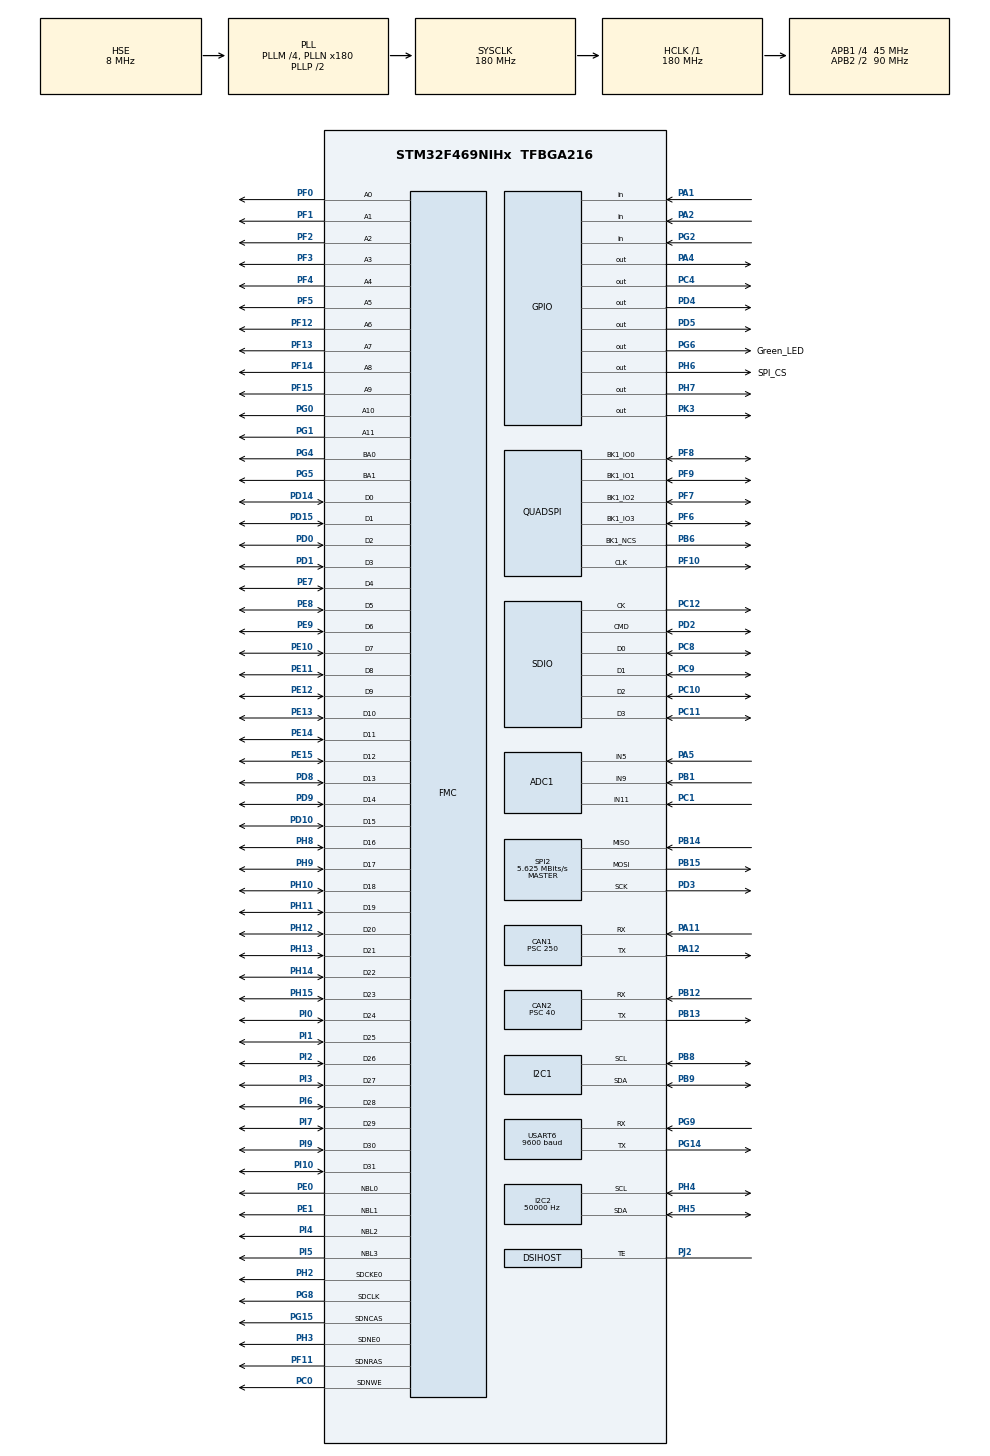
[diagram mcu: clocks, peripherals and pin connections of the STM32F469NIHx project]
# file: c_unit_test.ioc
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ADC1.Channel-1\#ChannelRegularConversion=ADC_CHANNEL_5
ADC1.Channel-2\#ChannelRegularConversion=ADC_CHANNEL_9
ADC1.Channel-3\#ChannelRegularConversion=ADC_CHANNEL_11
ADC1.ContinuousConvMode=ENABLE
ADC1.InjNumberOfConversion=0
ADC1.NbrOfConversion=3
ADC1.NbrOfConversionFlag=1
ADC1.Rank-1\#ChannelRegularConversion=1
ADC1.Rank-2\#ChannelRegularConversion=2
ADC1.Rank-3\#ChannelRegularConversion=3
ADC1.SamplingTime-1\#ChannelRegularConversion=ADC_SAMPLETIME_56CYCLES
ADC1.SamplingTime-2\#ChannelRegularConversion=ADC_SAMPLETIME_84CYCLES
ADC1.SamplingTime-3\#ChannelRegularConversion=ADC_SAMPLETIME_112CYCLES
ADC1.ScanConvMode=ENABLE
ADC1.master=1
CAN1.BS1=CAN_BS1_7TQ
CAN1.CalculateBaudRate=20000
CAN1.CalculateTimeBit=50000
CAN1.CalculateTimeQuantum=5555.555555555556
CAN1.Prescaler=250
CAN2.BS1=CAN_BS1_7TQ
CAN2.CalculateBaudRate=125000
CAN2.CalculateTimeBit=8000
CAN2.CalculateTimeQuantum=888.8888888888889
CAN2.Prescaler=40
DMA2D.ColorMode=DMA2D_OUTPUT_ARGB8888
DSIHOST.AcknowledgeRequest=DSI_ACKNOWLEDGE_ENABLE
DSIHOST.AutomaticRefresh=DSI_AR_DISABLE
DSIHOST.CommandSize=200
DSIHOST.LPDcsLongWrite=DSI_LP_DLW_ENABLE
DSIHOST.LPDcsShortReadNoP=DSI_LP_DSR0P_ENABLE
DSIHOST.LPDcsShortWriteNoP=DSI_LP_DSW0P_ENABLE
DSIHOST.LPDcsShortWriteOneP=DSI_LP_DSW1P_ENABLE
DSIHOST.LPGenLongWrite=DSI_LP_GLW_ENABLE
DSIHOST.LPGenShortReadNoP=DSI_LP_GSR0P_ENABLE
DSIHOST.LPGenShortReadOneP=DSI_LP_GSR1P_ENABLE
DSIHOST.LPGenShortReadTwoP=DSI_LP_GSR2P_ENABLE
DSIHOST.LPGenShortWriteNoP=DSI_LP_GSW0P_ENABLE
DSIHOST.LPGenShortWriteOneP=DSI_LP_GSW1P_ENABLE
DSIHOST.LPGenShortWriteTwoP=DSI_LP_GSW2P_ENABLE
DSIHOST.LPMaxReadPacket=DSI_LP_MRDP_ENABLE
DSIHOST.NumberOfLanes=DSI_TWO_DATA_LANES
DSIHOST.TEAcknowledgeRequest=DSI_TE_ACKNOWLEDGE_ENABLE
DSIHOST.TimeoutCkdiv=1
DSIHOST_CKN.Mode=DSIHost_Adapted_TE
DSIHOST_CKN.Signal=DSIHOST_CKN
DSIHOST_CKP.Mode=DSIHost_Adapted_TE
DSIHOST_CKP.Signal=DSIHOST_CKP
DSIHOST_D0N.Mode=DSIHost_Adapted_TE
DSIHOST_D0N.Signal=DSIHOST_D0N
DSIHOST_D0P.Mode=DSIHost_Adapted_TE
DSIHOST_D0P.Signal=DSIHOST_D0P
DSIHOST_D1N.Mode=DSIHost_Adapted_TE
DSIHOST_D1N.Signal=DSIHOST_D1N
DSIHOST_D1P.Mode=DSIHost_Adapted_TE
DSIHOST_D1P.Signal=DSIHOST_D1P
Dma.Request0=SDIO_RX
Dma.Request1=SDIO_TX
Dma.SDIO_RX.0.Direction=DMA_PERIPH_TO_MEMORY
Dma.SDIO_RX.0.FIFOMode=DMA_FIFOMODE_ENABLE
Dma.SDIO_RX.0.FIFOThreshold=DMA_FIFO_THRESHOLD_FULL
Dma.SDIO_RX.0.Instance=DMA2_Stream3
Dma.SDIO_RX.0.MemBurst=DMA_MBURST_INC4
Dma.SDIO_RX.0.MemDataAlignment=DMA_MDATAALIGN_WORD
Dma.SDIO_RX.0.MemInc=DMA_MINC_ENABLE
Dma.SDIO_RX.0.Mode=DMA_PFCTRL
Dma.SDIO_RX.0.PeriphBurst=DMA_PBURST_INC4
Dma.SDIO_RX.0.PeriphDataAlignment=DMA_PDATAALIGN_WORD
Dma.SDIO_RX.0.PeriphInc=DMA_PINC_DISABLE
Dma.SDIO_RX.0.Priority=DMA_PRIORITY_VERY_HIGH
Dma.SDIO_TX.1.Direction=DMA_MEMORY_TO_PERIPH
Dma.SDIO_TX.1.FIFOMode=DMA_FIFOMODE_ENABLE
Dma.SDIO_TX.1.FIFOThreshold=DMA_FIFO_THRESHOLD_FULL
Dma.SDIO_TX.1.Instance=DMA2_Stream6
Dma.SDIO_TX.1.MemBurst=DMA_MBURST_INC4
Dma.SDIO_TX.1.MemDataAlignment=DMA_MDATAALIGN_WORD
Dma.SDIO_TX.1.MemInc=DMA_MINC_ENABLE
Dma.SDIO_TX.1.Mode=DMA_PFCTRL
Dma.SDIO_TX.1.PeriphBurst=DMA_PBURST_INC4
Dma.SDIO_TX.1.PeriphDataAlignment=DMA_PDATAALIGN_WORD
Dma.SDIO_TX.1.PeriphInc=DMA_PINC_DISABLE
Dma.SDIO_TX.1.Priority=DMA_PRIORITY_VERY_HIGH
FATFS.BSP.number=1
FATFS._FS_LOCK=2
FATFS._FS_REENTRANT=0
FATFS._FS_TIMEOUT=10000
FATFS._LFN_UNICODE=0
FATFS._MAX_SS=512
FATFS._MIN_SS=512
FATFS._STRF_ENCODE=3
FATFS._USE_CHMOD=0
FATFS._USE_EXPAND=0
FATFS._USE_LFN=2
FATFS0.BSP.STBoard=false
FATFS0.BSP.api=Unknown
FATFS0.BSP.instance=PG2
FATFS0.BSP.ip=GPIO
FATFS0.BSP.mode=Input
FATFS0.BSP.name=Detect_SDIO
FATFS0.BSP.solution=PG2
FMC.CASLatency1=FMC_SDRAM_CAS_LATENCY_3
FMC.ExitSelfRefreshDelay1=7
FMC.LoadToActiveDelay1=2
FMC.RCDDelay1=2
FMC.RPDelay1=2
FMC.ReadBurst1=FMC_SDRAM_RBURST_ENABLE
FMC.ReadPipeDelay1=FMC_SDRAM_RPIPE_DELAY_2
FMC.RowCycleDelay1=7
FMC.SelfRefreshTime1=4
FMC.WriteRecoveryTime1=3
FREERTOS.BinarySemaphores01=BinarySemCAN,Dynamic,NULL
FREERTOS.INCLUDE_uxTaskGetStackHighWaterMark2=1
FREERTOS.Tasks01=defaultTask,26,128,StartDefaultTask,Default,NULL,Dynamic,NULL,NULL;StateTask,27,128,StartStateTask,Default,NULL,Dynamic,NULL,NULL;OutTask,28,128,StartOutTask,Default,NULL,Dynamic,NULL,NULL;ModeTask,29,128,StartModeTask,Default,NULL,Dynamic,NULL,NULL;TimeTask,31,256,StartTimeTask,Default,NULL,Dynamic,NULL,NULL;CAN2TxTask,26,128,StartCAN2TxTask,Default,NULL,Dynamic,NULL,NULL;SDTask,24,512,StartSDTask,Default,NULL,Dynamic,NULL,NULL;CAN1RxTxTask,25,256,StartCAN1RxTxTask,Default,NULL,Dynamic,NULL,NULL;AlarmTask,30,128,StartAlarmTask,Default,NULL,Dynamic,NULL,NULL;RequestTask,8,128,StartRequestTask,Default,NULL,Dynamic,NULL,NULL;CAN1_ReceiveTas,26,128,StartCAN1_ReceiveTask,Default,NULL,Dynamic,NULL,NULL;CAN1_TransmitTa,26,128,StartCAN1_TransmitTask,Default,NULL,Dynamic,NULL,NULL;AcquisitionTask,26,128,StartAcquisitionTask,Default,NULL,Dynamic,NULL,NULL
FREERTOS.configCHECK_FOR_STACK_OVERFLOW=0
FREERTOS.configGENERATE_RUN_TIME_STATS=1
FREERTOS.configRECORD_STACK_HIGH_ADDRESS=1
FREERTOS.configTOTAL_HEAP_SIZE=32768
FREERTOS.configUSE_APPLICATION_TASK_TAG=1
FREERTOS.configUSE_IDLE_HOOK=1
FREERTOS.configUSE_NEWLIB_REENTRANT=1
FREERTOS.configUSE_STATS_FORMATTING_FUNCTIONS=1
FREERTOS.configUSE_TRACE_FACILITY=1
I2C1.I2C_Mode=I2C_Fast
I2C2.ClockSpeed=50000
LTDC.ActiveW=200
LTDC.Alpha_L0=255
LTDC.FBStartAdress_L0=0xC0000000
LTDC.HBP=1
LTDC.HFP=1
LTDC.HSync=2
LTDC.ImageHeight_L0=480
LTDC.ImageWidth_L0=200
LTDC.Layers=0
LTDC.PixelFormat_L0=LTDC_PIXEL_FORMAT_RGB565
LTDC.VBP=1
LTDC.VFP=1
LTDC.VSync=2
LTDC.WindowX1_L0=200
LTDC.WindowY1_L0=480
Mcu.Family=STM32F4
Mcu.Name=STM32F469NIHx
Mcu.Package=TFBGA216
NVIC.CAN2_RX1_IRQn=true\:5\:0\:false\:false\:true\:true\:true\:true\:true
NVIC.DMA2D_IRQn=true\:5\:0\:true\:false\:true\:false\:true\:true\:true
NVIC.DMA2_Stream3_IRQn=true\:5\:0\:false\:false\:true\:true\:false\:true\:true
NVIC.DMA2_Stream6_IRQn=true\:5\:0\:false\:false\:true\:true\:false\:true\:true
NVIC.DSI_IRQn=true\:5\:0\:true\:false\:true\:false\:true\:true\:true
NVIC.LTDC_IRQn=true\:5\:0\:true\:false\:true\:false\:true\:true\:true
NVIC.PriorityGroup=NVIC_PRIORITYGROUP_4
NVIC.SDIO_IRQn=true\:5\:0\:true\:false\:true\:true\:true\:true\:true
NVIC.TIM2_IRQn=true\:5\:0\:false\:false\:true\:true\:true\:true\:true
NVIC.TIM6_DAC_IRQn=true\:0\:0\:false\:false\:true\:false\:false\:true\:true
NVIC.TIM7_IRQn=true\:5\:0\:false\:false\:true\:true\:true\:true\:true
NVIC.TimeBase=TIM6_DAC_IRQn
NVIC.TimeBaseIP=TIM6
PA1.Signal=GPIO_Input
PA11.Mode=CAN_Activate
PA11.Signal=CAN1_RX
PA12.Mode=CAN_Activate
PA12.Signal=CAN1_TX
PA2.Signal=GPIO_Input
PA4.Signal=GPIO_Output
PA5.Signal=ADCx_IN5
PA6.Signal=SPI1_MISO
PA7.Signal=SPI1_MOSI
PB1.Signal=ADCx_IN9
PB12.Mode=CAN_Activate
PB12.Signal=CAN2_RX
PB13.Mode=CAN_Activate
PB13.Signal=CAN2_TX
PB14.GPIO_PuPd=GPIO_PULLUP
PB14.GPIO_Speed=GPIO_SPEED_FREQ_HIGH
PB14.Mode=Full_Duplex_Master
PB14.Signal=SPI2_MISO
PB15.GPIO_PuPd=GPIO_PULLUP
PB15.GPIO_Speed=GPIO_SPEED_FREQ_HIGH
PB15.Mode=Full_Duplex_Master
PB15.Signal=SPI2_MOSI
PB6.Mode=Single Bank 1
PB6.Signal=QUADSPI_BK1_NCS
PB8.GPIO_Pu=GPIO_PULLUP
PB8.Mode=I2C
PB8.Signal=I2C1_SCL
PB9.GPIO_Pu=GPIO_PULLUP
PB9.Mode=I2C
PB9.Signal=I2C1_SDA
PC0.Signal=FMC_SDNWE
PC1.Signal=ADCx_IN11
PC10.GPIO_PuPd=GPIO_PULLUP
PC10.Mode=SD_4_bits_Wide_bus
PC10.Signal=SDIO_D2
PC11.GPIO_PuPd=GPIO_PULLUP
PC11.Mode=SD_4_bits_Wide_bus
PC11.Signal=SDIO_D3
PC12.Mode=SD_4_bits_Wide_bus
PC12.Signal=SDIO_CK
PC4.Signal=GPIO_Output
PC8.GPIO_PuPd=GPIO_PULLUP
PC8.Mode=SD_4_bits_Wide_bus
PC8.Signal=SDIO_D0
PC9.GPIO_PuPd=GPIO_PULLUP
PC9.Mode=SD_4_bits_Wide_bus
PC9.Signal=SDIO_D1
PD0.Signal=FMC_D2_DA2
PD1.Signal=FMC_D3_DA3
PD10.Signal=FMC_D15_DA15
PD14.Signal=FMC_D0_DA0
PD15.Signal=FMC_D1_DA1
PD2.GPIO_PuPd=GPIO_PULLUP
PD2.Mode=SD_4_bits_Wide_bus
PD2.Signal=SDIO_CMD
PD3.GPIO_Speed=GPIO_SPEED_FREQ_HIGH
PD3.Mode=Full_Duplex_Master
PD3.Signal=SPI2_SCK
PD4.GPIO_ModeDefaultOutputPP=GPIO_MODE_OUTPUT_OD
PD4.GPIO_PuPd=GPIO_NOPULL
PD4.PinState=GPIO_PIN_SET
PD4.Signal=GPIO_Output
PD5.GPIO_ModeDefaultOutputPP=GPIO_MODE_OUTPUT_OD
PD5.GPIO_PuPd=GPIO_NOPULL
PD5.PinState=GPIO_PIN_SET
PD5.Signal=GPIO_Output
PD8.Signal=FMC_D13_DA13
PD9.Signal=FMC_D14_DA14
PE0.Signal=FMC_NBL0
PE1.Signal=FMC_NBL1
PE10.Signal=FMC_D7_DA7
PE11.Signal=FMC_D8_DA8
PE12.Signal=FMC_D9_DA9
PE13.Signal=FMC_D10_DA10
PE14.Signal=FMC_D11_DA11
PE15.Signal=FMC_D12_DA12
PE7.Signal=FMC_D4_DA4
PE8.Signal=FMC_D5_DA5
PE9.Signal=FMC_D6_DA6
PF0.Signal=FMC_A0
PF1.Signal=FMC_A1
PF10.Mode=Single Bank 1
PF10.Signal=QUADSPI_CLK
PF11.Signal=FMC_SDNRAS
PF12.Signal=FMC_A6
PF13.Signal=FMC_A7
PF14.Signal=FMC_A8
PF15.Signal=FMC_A9
PF2.Signal=FMC_A2
PF3.Signal=FMC_A3
PF4.Signal=FMC_A4
PF5.Signal=FMC_A5
PF6.Mode=Single Bank 1
PF6.Signal=QUADSPI_BK1_IO3
PF7.Mode=Single Bank 1
PF7.Signal=QUADSPI_BK1_IO2
PF8.Mode=Single Bank 1
PF8.Signal=QUADSPI_BK1_IO0
PF9.Mode=Single Bank 1
PF9.Signal=QUADSPI_BK1_IO1
PG0.Signal=FMC_A10
PG1.Signal=FMC_A11
PG14.Mode=Asynchronous
PG14.Signal=USART6_TX
PG15.Signal=FMC_SDNCAS
PG2.Signal=GPIO_Input
PG4.Signal=FMC_A14_BA0
PG5.Signal=FMC_A15_BA1
PG6.GPIO_Label=Green_LED
PG6.GPIO_ModeDefaultOutputPP=GPIO_MODE_OUTPUT_OD
PG6.GPIO_PuPd=GPIO_NOPULL
PG6.PinState=GPIO_PIN_SET
PG6.Signal=GPIO_Output
PG8.Signal=FMC_SDCLK
PG9.Mode=Asynchronous
PG9.Signal=USART6_RX
PH0/OSC_IN.Mode=HSE-External-Oscillator
PH0/OSC_IN.Signal=RCC_OSC_IN
PH1/OSC_OUT.Mode=HSE-External-Oscillator
PH1/OSC_OUT.Signal=RCC_OSC_OUT
PH10.Signal=FMC_D18
PH11.Signal=FMC_D19
PH12.Signal=FMC_D20
PH13.Signal=FMC_D21
PH14.Signal=FMC_D22
PH15.Signal=FMC_D23
PH2.Mode=SdramChipSelect1_1
PH2.Signal=FMC_SDCKE0
PH3.Mode=SdramChipSelect1_1
PH3.Signal=FMC_SDNE0
PH4.Mode=I2C
PH4.Signal=I2C2_SCL
PH5.Mode=I2C
PH5.Signal=I2C2_SDA
PH6.GPIO_Label=SPI_CS
PH6.GPIO_ModeDefaultOutputPP=GPIO_MODE_OUTPUT_PP
PH6.GPIO_PuPd=GPIO_NOPULL
PH6.GPIO_Speed=GPIO_SPEED_FREQ_LOW
PH6.PinState=GPIO_PIN_RESET
PH6.Signal=GPIO_Output
PH7.GPIO_ModeDefaultOutputPP=GPIO_MODE_OUTPUT_OD
PH7.GPIO_Speed=GPIO_SPEED_FREQ_VERY_HIGH
PH7.PinState=GPIO_PIN_RESET
PH7.Signal=GPIO_Output
PH8.Signal=FMC_D16
PH9.Signal=FMC_D17
PI0.Signal=FMC_D24
PI1.Signal=FMC_D25
PI10.Signal=FMC_D31
PI2.Signal=FMC_D26
PI3.Signal=FMC_D27
PI4.Signal=FMC_NBL2
PI5.Signal=FMC_NBL3
PI6.Signal=FMC_D28
PI7.Signal=FMC_D29
PI9.Signal=FMC_D30
PJ2.Mode=DSIHost_Adapted_TE
PJ2.Signal=DSIHOST_TE
PK3.Signal=GPIO_Output
ProjectManager.HeapSize=0x1000
ProjectManager.StackSize=0x1000
ProjectManager.TargetToolchain=STM32CubeIDE
QUADSPI.ChipSelectHighTime=QSPI_CS_HIGH_TIME_5_CYCLE
QUADSPI.ClockPrescaler=1
QUADSPI.FlashSize=27
QUADSPI.SampleShifting=QSPI_SAMPLE_SHIFTING_HALFCYCLE
RCC.AHBFreq_Value=180000000
RCC.APB1CLKDivider=RCC_HCLK_DIV4
RCC.APB1Freq_Value=45000000
RCC.APB1TimFreq_Value=90000000
RCC.APB2CLKDivider=RCC_HCLK_DIV2
RCC.APB2Freq_Value=90000000
RCC.APB2TimFreq_Value=180000000
RCC.CortexFreq_Value=180000000
RCC.HCLKFreq_Value=180000000
RCC.HSE_VALUE=8000000
RCC.PLLDSIIDF=DSI_PLL_IN_DIV2
RCC.PLLDSINDIV=125
RCC.PLLM=4
RCC.PLLN=180
RCC.PLLQ=8
RCC.PLLR=6
RCC.PLLSAIN=50
RCC.PLLSourceVirtual=RCC_PLLSOURCE_HSE
RCC.SYSCLKFreq_VALUE=180000000
RCC.SYSCLKSource=RCC_SYSCLKSOURCE_PLLCLK
RCC.USBFreq_Value=45000000
RCC.VCOOutputFreq_Value=360000000
SDIO.ClockDiv=0
SH.ADCx_IN11.0=ADC1_IN11,IN11
SH.ADCx_IN5.0=ADC1_IN5,IN5
SH.ADCx_IN5.1=ADC2_IN5
SH.ADCx_IN9.0=ADC1_IN9,IN9
SH.FMC_A0.0=FMC_A0,12b-sda1
SH.FMC_A1.0=FMC_A1,12b-sda1
SH.FMC_A10.0=FMC_A10,12b-sda1
SH.FMC_A11.0=FMC_A11,12b-sda1
SH.FMC_A14_BA0.0=FMC_BA0,FourSdramBanks1
SH.FMC_A15_BA1.0=FMC_BA1,FourSdramBanks1
SH.FMC_A2.0=FMC_A2,12b-sda1
SH.FMC_A3.0=FMC_A3,12b-sda1
SH.FMC_A4.0=FMC_A4,12b-sda1
SH.FMC_A5.0=FMC_A5,12b-sda1
SH.FMC_A6.0=FMC_A6,12b-sda1
SH.FMC_A7.0=FMC_A7,12b-sda1
SH.FMC_A8.0=FMC_A8,12b-sda1
SH.FMC_A9.0=FMC_A9,12b-sda1
SH.FMC_D0_DA0.0=FMC_D0,sd-32b-d1
SH.FMC_D10_DA10.0=FMC_D10,sd-32b-d1
SH.FMC_D11_DA11.0=FMC_D11,sd-32b-d1
SH.FMC_D12_DA12.0=FMC_D12,sd-32b-d1
SH.FMC_D13_DA13.0=FMC_D13,sd-32b-d1
SH.FMC_D14_DA14.0=FMC_D14,sd-32b-d1
SH.FMC_D15_DA15.0=FMC_D15,sd-32b-d1
SH.FMC_D16.0=FMC_D16,sd-32b-d1
SH.FMC_D17.0=FMC_D17,sd-32b-d1
SH.FMC_D18.0=FMC_D18,sd-32b-d1
SH.FMC_D19.0=FMC_D19,sd-32b-d1
SH.FMC_D1_DA1.0=FMC_D1,sd-32b-d1
SH.FMC_D20.0=FMC_D20,sd-32b-d1
SH.FMC_D21.0=FMC_D21,sd-32b-d1
SH.FMC_D22.0=FMC_D22,sd-32b-d1
SH.FMC_D23.0=FMC_D23,sd-32b-d1
SH.FMC_D24.0=FMC_D24,sd-32b-d1
SH.FMC_D25.0=FMC_D25,sd-32b-d1
SH.FMC_D26.0=FMC_D26,sd-32b-d1
SH.FMC_D27.0=FMC_D27,sd-32b-d1
SH.FMC_D28.0=FMC_D28,sd-32b-d1
SH.FMC_D29.0=FMC_D29,sd-32b-d1
SH.FMC_D2_DA2.0=FMC_D2,sd-32b-d1
SH.FMC_D30.0=FMC_D30,sd-32b-d1
SH.FMC_D31.0=FMC_D31,sd-32b-d1
SH.FMC_D3_DA3.0=FMC_D3,sd-32b-d1
SH.FMC_D4_DA4.0=FMC_D4,sd-32b-d1
SH.FMC_D5_DA5.0=FMC_D5,sd-32b-d1
SH.FMC_D6_DA6.0=FMC_D6,sd-32b-d1
SH.FMC_D7_DA7.0=FMC_D7,sd-32b-d1
SH.FMC_D8_DA8.0=FMC_D8,sd-32b-d1
SH.FMC_D9_DA9.0=FMC_D9,sd-32b-d1
SH.FMC_NBL0.0=FMC_NBL0,Sd4ByteEnable1
SH.FMC_NBL1.0=FMC_NBL1,Sd4ByteEnable1
SH.FMC_NBL2.0=FMC_NBL2,Sd4ByteEnable1
SH.FMC_NBL3.0=FMC_NBL3,Sd4ByteEnable1
SH.FMC_SDCLK.0=FMC_SDCLK,12b-sda1
SH.FMC_SDNCAS.0=FMC_SDNCAS,12b-sda1
SH.FMC_SDNRAS.0=FMC_SDNRAS,12b-sda1
SH.FMC_SDNWE.0=FMC_SDNWE,12b-sda1
SPI2.BaudRatePrescaler=SPI_BAUDRATEPRESCALER_8
SPI2.CalculateBaudRate=5.625 MBits/s
SPI2.Direction=SPI_DIRECTION_2LINES
SPI2.Mode=SPI_MODE_MASTER
SPI2.VirtualType=VM_MASTER
TIM2.Period=10000
TIM2.Prescaler=9000 -1
TIM7.Period=99
TIM7.Prescaler=179
USART6.BaudRate=9600
USART6.Parity=PARITY_EVEN
USART6.VirtualMode=VM_ASYNC
USART6.WordLength=WORDLENGTH_9B
VP_CRC_VS_CRC.Mode=CRC_Activate
VP_DMA2D_VS_DMA2D.Mode=DMA2D_Activate
VP_FATFS_VS_SDIO.Mode=SDIO
VP_FREERTOS_VS_CMSIS_V2.Mode=CMSIS_V2
VP_LTDC_DSIMode.Mode=RGB565
VP_SYS_VS_tim6.Mode=TIM6
VP_TIM2_VS_ClockSourceINT.Mode=Internal
VP_TIM7_VS_ClockSourceINT.Mode=Enable_Timer
board=custom

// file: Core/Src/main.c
/* USER CODE BEGIN Header */
/**
  ******************************************************************************
  * @file           : main.c
  * @brief          : Main program body
  ******************************************************************************
  * @attention
  *
  * Copyright (c) 2023 STMicroelectronics.
  * All rights reserved.
  *
  * This software is licensed under terms that can be found in the LICENSE file
  * in the root directory of this software component.
  * If no LICENSE file comes with this software, it is provided AS-IS.
  *
  ******************************************************************************
  */
/* USER CODE END Header */
#include <main.h>
#include "cmsis_os.h"
#include "fatfs.h"

/* USER CODE BEGIN Includes */
#include "../average/average.h"
/* USER CODE END Includes */

ADC_HandleTypeDef hadc1;

CAN_HandleTypeDef hcan1;
CAN_HandleTypeDef hcan2;

CRC_HandleTypeDef hcrc;

DMA2D_HandleTypeDef hdma2d;

DSI_HandleTypeDef hdsi;

I2C_HandleTypeDef hi2c1;
I2C_HandleTypeDef hi2c2;

LTDC_HandleTypeDef hltdc;

QSPI_HandleTypeDef hqspi;

SD_HandleTypeDef hsd;
DMA_HandleTypeDef hdma_sdio_rx;
DMA_HandleTypeDef hdma_sdio_tx;

SPI_HandleTypeDef hspi2;

TIM_HandleTypeDef htim2;
TIM_HandleTypeDef htim7;

UART_HandleTypeDef huart6;

SDRAM_HandleTypeDef hsdram1;

/* Definitions for defaultTask */
osThreadId_t defaultTaskHandle;
const osThreadAttr_t defaultTask_attributes = {
  .name = "defaultTask",
  .stack_size = 128 * 4,
  .priority = (osPriority_t) osPriorityNormal2,
};
/* Definitions for StateTask */
osThreadId_t StateTaskHandle;
const osThreadAttr_t StateTask_attributes = {
  .name = "StateTask",
  .stack_size = 128 * 4,
  .priority = (osPriority_t) osPriorityNormal3,
};
/* Definitions for OutTask */
osThreadId_t OutTaskHandle;
const osThreadAttr_t OutTask_attributes = {
  .name = "OutTask",
  .stack_size = 128 * 4,
  .priority = (osPriority_t) osPriorityNormal4,
};
/* Definitions for ModeTask */
osThreadId_t ModeTaskHandle;
const osThreadAttr_t ModeTask_attributes = {
  .name = "ModeTask",
  .stack_size = 128 * 4,
  .priority = (osPriority_t) osPriorityNormal5,
};
/* Definitions for TimeTask */
osThreadId_t TimeTaskHandle;
const osThreadAttr_t TimeTask_attributes = {
  .name = "TimeTask",
  .stack_size = 256 * 4,
  .priority = (osPriority_t) osPriorityNormal7,
};
/* Definitions for CAN2TxTask */
osThreadId_t CAN2TxTaskHandle;
const osThreadAttr_t CAN2TxTask_attributes = {
  .name = "CAN2TxTask",
  .stack_size = 128 * 4,
  .priority = (osPriority_t) osPriorityNormal2,
};
/* Definitions for SDTask */
osThreadId_t SDTaskHandle;
const osThreadAttr_t SDTask_attributes = {
  .name = "SDTask",
  .stack_size = 512 * 4,
  .priority = (osPriority_t) osPriorityNormal,
};
/* Definitions for CAN1RxTxTask */
osThreadId_t CAN1RxTxTaskHandle;
const osThreadAttr_t CAN1RxTxTask_attributes = {
  .name = "CAN1RxTxTask",
  .stack_size = 256 * 4,
  .priority = (osPriority_t) osPriorityNormal1,
};
/* Definitions for AlarmTask */
osThreadId_t AlarmTaskHandle;
const osThreadAttr_t AlarmTask_attributes = {
  .name = "AlarmTask",
  .stack_size = 128 * 4,
  .priority = (osPriority_t) osPriorityNormal6,
};
/* Definitions for RequestTask */
osThreadId_t RequestTaskHandle;
const osThreadAttr_t RequestTask_attributes = {
  .name = "RequestTask",
  .stack_size = 128 * 4,
  .priority = (osPriority_t) osPriorityLow,
};
/* Definitions for CAN1_ReceiveTas */
osThreadId_t CAN1_ReceiveTasHandle;
const osThreadAttr_t CAN1_ReceiveTas_attributes = {
  .name = "CAN1_ReceiveTas",
  .stack_size = 128 * 4,
  .priority = (osPriority_t) osPriorityNormal2,
};
/* Definitions for CAN1_TransmitTa */
osThreadId_t CAN1_TransmitTaHandle;
const osThreadAttr_t CAN1_TransmitTa_attributes = {
  .name = "CAN1_TransmitTa",
  .stack_size = 128 * 4,
  .priority = (osPriority_t) osPriorityNormal2,
};
/* Definitions for AcquisitionTask */
osThreadId_t AcquisitionTaskHandle;
const osThreadAttr_t AcquisitionTask_attributes = {
  .name = "AcquisitionTask",
  .stack_size = 128 * 4,
  .priority = (osPriority_t) osPriorityNormal2,
};
/* Definitions for BinarySemCAN */
osSemaphoreId_t BinarySemCANHandle;
const osSemaphoreAttr_t BinarySemCAN_attributes = {
  .name = "BinarySemCAN"
};

void SystemClock_Config(void);
static void MX_GPIO_Init(void);
static void MX_DMA_Init(void);
static void MX_DMA2D_Init(void);
static void MX_DSIHOST_DSI_Init(void);
static void MX_FMC_Init(void);
static void MX_LTDC_Init(void);
static void MX_QUADSPI_Init(void);
static void MX_I2C1_Init(void);
static void MX_CAN1_Init(void);
static void MX_CAN2_Init(void);
static void MX_SPI2_Init(void);
static void MX_TIM2_Init(void);
static void MX_I2C2_Init(void);
static void MX_USART6_UART_Init(void);
static void MX_SDIO_SD_Init(void);
static void MX_CRC_Init(void);
static void MX_TIM7_Init(void);
static void MX_ADC1_Init(void);
void StartDefaultTask(void *argument);
void StartStateTask(void *argument);
void StartOutTask(void *argument);
void StartModeTask(void *argument);
void StartTimeTask(void *argument);
void StartCAN2TxTask(void *argument);
void StartSDTask(void *argument);
void StartCAN1RxTxTask(void *argument);
void StartAlarmTask(void *argument);
void StartRequestTask(void *argument);
void StartCAN1_ReceiveTask(void *argument);
void StartCAN1_TransmitTask(void *argument);
void StartAcquisitionTask(void *argument);

int main(void)
{

  /* MCU Configuration--------------------------------------------------------*/

  /* Reset of all peripherals, Initializes the Flash interface and the Systick. */
  HAL_Init();

  /* Configure the system clock */
  SystemClock_Config();

  /* Initialize all configured peripherals */
  MX_GPIO_Init();
  MX_DMA_Init();
  MX_DMA2D_Init();
  MX_DSIHOST_DSI_Init();
  MX_FMC_Init();
  MX_LTDC_Init();
  MX_QUADSPI_Init();
  MX_I2C1_Init();
  MX_CAN1_Init();
  MX_CAN2_Init();
  MX_SPI2_Init();
  MX_TIM2_Init();
  MX_I2C2_Init();
  MX_USART6_UART_Init();
  MX_SDIO_SD_Init();
  MX_FATFS_Init();
  MX_CRC_Init();
  MX_TIM7_Init();
  MX_ADC1_Init();

  /* Init scheduler */
  osKernelInitialize();

  /* Create the semaphores(s) */
  /* creation of BinarySemCAN */
  BinarySemCANHandle = osSemaphoreNew(1, 1, &BinarySemCAN_attributes);

  /* Create the thread(s) */
  /* creation of defaultTask */
  defaultTaskHandle = osThreadNew(StartDefaultTask, NULL, &defaultTask_attributes);

  /* creation of StateTask */
  StateTaskHandle = osThreadNew(StartStateTask, NULL, &StateTask_attributes);

  /* creation of OutTask */
  OutTaskHandle = osThreadNew(StartOutTask, NULL, &OutTask_attributes);

  /* creation of ModeTask */
  ModeTaskHandle = osThreadNew(StartModeTask, NULL, &ModeTask_attributes);

  /* creation of TimeTask */
  TimeTaskHandle = osThreadNew(StartTimeTask, NULL, &TimeTask_attributes);

  /* creation of CAN2TxTask */
  CAN2TxTaskHandle = osThreadNew(StartCAN2TxTask, NULL, &CAN2TxTask_attributes);

  /* creation of SDTask */
  SDTaskHandle = osThreadNew(StartSDTask, NULL, &SDTask_attributes);

  /* creation of CAN1RxTxTask */
  CAN1RxTxTaskHandle = osThreadNew(StartCAN1RxTxTask, NULL, &CAN1RxTxTask_attributes);

  /* creation of AlarmTask */
  AlarmTaskHandle = osThreadNew(StartAlarmTask, NULL, &AlarmTask_attributes);

  /* creation of RequestTask */
  RequestTaskHandle = osThreadNew(StartRequestTask, NULL, &RequestTask_attributes);

  /* creation of CAN1_ReceiveTas */
  CAN1_ReceiveTasHandle = osThreadNew(StartCAN1_ReceiveTask, NULL, &CAN1_ReceiveTas_attributes);

  /* creation of CAN1_TransmitTa */
  CAN1_TransmitTaHandle = osThreadNew(StartCAN1_TransmitTask, NULL, &CAN1_TransmitTa_attributes);

  /* creation of AcquisitionTask */
  AcquisitionTaskHandle = osThreadNew(StartAcquisitionTask, NULL, &AcquisitionTask_attributes);

  /* Start scheduler */
  osKernelStart();

  /* We should never get here as control is now taken by the scheduler */
  /* Infinite loop */
  while (1)
  {

  }
}

void SystemClock_Config(void)
{
  RCC_OscInitTypeDef RCC_OscInitStruct = {0};
  RCC_ClkInitTypeDef RCC_ClkInitStruct = {0};

  /** Configure the main internal regulator output voltage
  */
  __HAL_RCC_PWR_CLK_ENABLE();
  __HAL_PWR_VOLTAGESCALING_CONFIG(PWR_REGULATOR_VOLTAGE_SCALE1);
  /** Initializes the RCC Oscillators according to the specified parameters
  * in the RCC_OscInitTypeDef structure.
  */
  RCC_OscInitStruct.OscillatorType = RCC_OSCILLATORTYPE_HSE;
  RCC_OscInitStruct.HSEState = RCC_HSE_ON;
  RCC_OscInitStruct.PLL.PLLState = RCC_PLL_ON;
  RCC_OscInitStruct.PLL.PLLSource = RCC_PLLSOURCE_HSE;
  RCC_OscInitStruct.PLL.PLLM = 4;
  RCC_OscInitStruct.PLL.PLLN = 180;
  RCC_OscInitStruct.PLL.PLLP = RCC_PLLP_DIV2;
  RCC_OscInitStruct.PLL.PLLQ = 8;
  RCC_OscInitStruct.PLL.PLLR = 6;
  if (HAL_RCC_OscConfig(&RCC_OscInitStruct) != HAL_OK)
  {
    Error_Handler();
  }
  /** Activate the Over-Drive mode
  */
  if (HAL_PWREx_EnableOverDrive() != HAL_OK)
  {
    Error_Handler();
  }
  /** Initializes the CPU, AHB and APB buses clocks
  */
  RCC_ClkInitStruct.ClockType = RCC_CLOCKTYPE_HCLK|RCC_CLOCKTYPE_SYSCLK
                              |RCC_CLOCKTYPE_PCLK1|RCC_CLOCKTYPE_PCLK2;
  RCC_ClkInitStruct.SYSCLKSource = RCC_SYSCLKSOURCE_PLLCLK;
  RCC_ClkInitStruct.AHBCLKDivider = RCC_SYSCLK_DIV1;
  RCC_ClkInitStruct.APB1CLKDivider = RCC_HCLK_DIV4;
  RCC_ClkInitStruct.APB2CLKDivider = RCC_HCLK_DIV2;

  if (HAL_RCC_ClockConfig(&RCC_ClkInitStruct, FLASH_LATENCY_5) != HAL_OK)
  {
    Error_Handler();
  }
}

static void MX_ADC1_Init(void)
{

  ADC_ChannelConfTypeDef sConfig = {0};

  /** Configure the global features of the ADC (Clock, Resolution, Data Alignment and number of conversion)
  */
  hadc1.Instance = ADC1;
  hadc1.Init.ClockPrescaler = ADC_CLOCK_SYNC_PCLK_DIV4;
  hadc1.Init.Resolution = ADC_RESOLUTION_12B;
  hadc1.Init.ScanConvMode = ENABLE;
  hadc1.Init.ContinuousConvMode = ENABLE;
  hadc1.Init.DiscontinuousConvMode = DISABLE;
  hadc1.Init.ExternalTrigConvEdge = ADC_EXTERNALTRIGCONVEDGE_NONE;
  hadc1.Init.ExternalTrigConv = ADC_SOFTWARE_START;
  hadc1.Init.DataAlign = ADC_DATAALIGN_RIGHT;
  hadc1.Init.NbrOfConversion = 3;
  hadc1.Init.DMAContinuousRequests = DISABLE;
  hadc1.Init.EOCSelection = ADC_EOC_SINGLE_CONV;
  if (HAL_ADC_Init(&hadc1) != HAL_OK)
  {
    Error_Handler();
  }
  /** Configure for the selected ADC regular channel its corresponding rank in the sequencer and its sample time.
  */
  sConfig.Channel = ADC_CHANNEL_5;
  sConfig.Rank = 1;
  sConfig.SamplingTime = ADC_SAMPLETIME_56CYCLES;
  if (HAL_ADC_ConfigChannel(&hadc1, &sConfig) != HAL_OK)
  {
    Error_Handler();
  }
  /** Configure for the selected ADC regular channel its corresponding rank in the sequencer and its sample time.
  */
  sConfig.Channel = ADC_CHANNEL_9;
  sConfig.Rank = 2;
  sConfig.SamplingTime = ADC_SAMPLETIME_84CYCLES;
  if (HAL_ADC_ConfigChannel(&hadc1, &sConfig) != HAL_OK)
  {
    Error_Handler();
  }
  /** Configure for the selected ADC regular channel its corresponding rank in the sequencer and its sample time.
  */
  sConfig.Channel = ADC_CHANNEL_11;
  sConfig.Rank = 3;
  sConfig.SamplingTime = ADC_SAMPLETIME_112CYCLES;
  if (HAL_ADC_ConfigChannel(&hadc1, &sConfig) != HAL_OK)
  {
    Error_Handler();
  }

}

static void MX_CAN1_Init(void)
{

  hcan1.Instance = CAN1;
  hcan1.Init.Prescaler = 250;
  hcan1.Init.Mode = CAN_MODE_NORMAL;
  hcan1.Init.SyncJumpWidth = CAN_SJW_1TQ;
  hcan1.Init.TimeSeg1 = CAN_BS1_7TQ;
  hcan1.Init.TimeSeg2 = CAN_BS2_1TQ;
  hcan1.Init.TimeTriggeredMode = DISABLE;
  hcan1.Init.AutoBusOff = DISABLE;
  hcan1.Init.AutoWakeUp = DISABLE;
  hcan1.Init.AutoRetransmission = DISABLE;
  hcan1.Init.ReceiveFifoLocked = DISABLE;
  hcan1.Init.TransmitFifoPriority = DISABLE;
  if (HAL_CAN_Init(&hcan1) != HAL_OK)
  {
    Error_Handler();
  }

}

static void MX_CAN2_Init(void)
{

  hcan2.Instance = CAN2;
  hcan2.Init.Prescaler = 40;
  hcan2.Init.Mode = CAN_MODE_NORMAL;
  hcan2.Init.SyncJumpWidth = CAN_SJW_1TQ;
  hcan2.Init.TimeSeg1 = CAN_BS1_7TQ;
  hcan2.Init.TimeSeg2 = CAN_BS2_1TQ;
  hcan2.Init.TimeTriggeredMode = DISABLE;
  hcan2.Init.AutoBusOff = DISABLE;
  hcan2.Init.AutoWakeUp = DISABLE;
  hcan2.Init.AutoRetransmission = DISABLE;
  hcan2.Init.ReceiveFifoLocked = DISABLE;
  hcan2.Init.TransmitFifoPriority = DISABLE;
  if (HAL_CAN_Init(&hcan2) != HAL_OK)
  {
    Error_Handler();
  }

}

static void MX_CRC_Init(void)
{

  hcrc.Instance = CRC;
  if (HAL_CRC_Init(&hcrc) != HAL_OK)
  {
    Error_Handler();
  }

}

static void MX_DMA2D_Init(void)
{

  hdma2d.Instance = DMA2D;
  hdma2d.Init.Mode = DMA2D_M2M;
  hdma2d.Init.ColorMode = DMA2D_OUTPUT_ARGB8888;
  hdma2d.Init.OutputOffset = 0;
  hdma2d.LayerCfg[1].InputOffset = 0;
  hdma2d.LayerCfg[1].InputColorMode = DMA2D_INPUT_ARGB8888;
  hdma2d.LayerCfg[1].AlphaMode = DMA2D_NO_MODIF_ALPHA;
  hdma2d.LayerCfg[1].InputAlpha = 0;
  if (HAL_DMA2D_Init(&hdma2d) != HAL_OK)
  {
    Error_Handler();
  }
  if (HAL_DMA2D_ConfigLayer(&hdma2d, 1) != HAL_OK)
  {
    Error_Handler();
  }

}

static void MX_DSIHOST_DSI_Init(void)
{

  DSI_PLLInitTypeDef PLLInit = {0};
  DSI_HOST_TimeoutTypeDef HostTimeouts = {0};
  DSI_PHY_TimerTypeDef PhyTimings = {0};
  DSI_LPCmdTypeDef LPCmd = {0};
  DSI_CmdCfgTypeDef CmdCfg = {0};

  hdsi.Instance = DSI;
  hdsi.Init.AutomaticClockLaneControl = DSI_AUTO_CLK_LANE_CTRL_DISABLE;
  hdsi.Init.TXEscapeCkdiv = 4;
  hdsi.Init.NumberOfLanes = DSI_TWO_DATA_LANES;
  PLLInit.PLLNDIV = 125;
  PLLInit.PLLIDF = DSI_PLL_IN_DIV2;
  PLLInit.PLLODF = DSI_PLL_OUT_DIV1;
  if (HAL_DSI_Init(&hdsi, &PLLInit) != HAL_OK)
  {
    Error_Handler();
  }
  HostTimeouts.TimeoutCkdiv = 1;
  HostTimeouts.HighSpeedTransmissionTimeout = 0;
  HostTimeouts.LowPowerReceptionTimeout = 0;
  HostTimeouts.HighSpeedReadTimeout = 0;
  HostTimeouts.LowPowerReadTimeout = 0;
  HostTimeouts.HighSpeedWriteTimeout = 0;
  HostTimeouts.HighSpeedWritePrespMode = DSI_HS_PM_DISABLE;
  HostTimeouts.LowPowerWriteTimeout = 0;
  HostTimeouts.BTATimeout = 0;
  if (HAL_DSI_ConfigHostTimeouts(&hdsi, &HostTimeouts) != HAL_OK)
  {
    Error_Handler();
  }
  PhyTimings.ClockLaneHS2LPTime = 28;
  PhyTimings.ClockLaneLP2HSTime = 33;
  PhyTimings.DataLaneHS2LPTime = 15;
  PhyTimings.DataLaneLP2HSTime = 25;
  PhyTimings.DataLaneMaxReadTime = 0;
  PhyTimings.StopWaitTime = 0;
  if (HAL_DSI_ConfigPhyTimer(&hdsi, &PhyTimings) != HAL_OK)
  {
    Error_Handler();
  }
  if (HAL_DSI_ConfigFlowControl(&hdsi, DSI_FLOW_CONTROL_BTA) != HAL_OK)
  {
    Error_Handler();
  }
  if (HAL_DSI_SetLowPowerRXFilter(&hdsi, 10000) != HAL_OK)
  {
    Error_Handler();
  }
  if (HAL_DSI_ConfigErrorMonitor(&hdsi, HAL_DSI_ERROR_NONE) != HAL_OK)
  {
    Error_Handler();
  }
  LPCmd.LPGenShortWriteNoP = DSI_LP_GSW0P_ENABLE;
  LPCmd.LPGenShortWriteOneP = DSI_LP_GSW1P_ENABLE;
  LPCmd.LPGenShortWriteTwoP = DSI_LP_GSW2P_ENABLE;
  LPCmd.LPGenShortReadNoP = DSI_LP_GSR0P_ENABLE;
  LPCmd.LPGenShortReadOneP = DSI_LP_GSR1P_ENABLE;
  LPCmd.LPGenShortReadTwoP = DSI_LP_GSR2P_ENABLE;
  LPCmd.LPGenLongWrite = DSI_LP_GLW_ENABLE;
  LPCmd.LPDcsShortWriteNoP = DSI_LP_DSW0P_ENABLE;
  LPCmd.LPDcsShortWriteOneP = DSI_LP_DSW1P_ENABLE;
  LPCmd.LPDcsShortReadNoP = DSI_LP_DSR0P_ENABLE;
  LPCmd.LPDcsLongWrite = DSI_LP_DLW_ENABLE;
  LPCmd.LPMaxReadPacket = DSI_LP_MRDP_ENABLE;
  LPCmd.AcknowledgeRequest = DSI_ACKNOWLEDGE_ENABLE;
  if (HAL_DSI_ConfigCommand(&hdsi, &LPCmd) != HAL_OK)
  {
    Error_Handler();
  }
  CmdCfg.VirtualChannelID = 0;
  CmdCfg.ColorCoding = DSI_RGB565;
  CmdCfg.CommandSize = 200;
  CmdCfg.TearingEffectSource = DSI_TE_EXTERNAL;
  CmdCfg.TearingEffectPolarity = DSI_TE_RISING_EDGE;
  CmdCfg.HSPolarity = DSI_HSYNC_ACTIVE_LOW;
  CmdCfg.VSPolarity = DSI_VSYNC_ACTIVE_LOW;
  CmdCfg.DEPolarity = DSI_DATA_ENABLE_ACTIVE_HIGH;
  CmdCfg.VSyncPol = DSI_VSYNC_FALLING;
  CmdCfg.AutomaticRefresh = DSI_AR_DISABLE;
  CmdCfg.TEAcknowledgeRequest = DSI_TE_ACKNOWLEDGE_ENABLE;
  if (HAL_DSI_ConfigAdaptedCommandMode(&hdsi, &CmdCfg) != HAL_OK)
  {
    Error_Handler();
  }
  if (HAL_DSI_SetGenericVCID(&hdsi, 0) != HAL_OK)
  {
    Error_Handler();
  }

}

static void MX_I2C1_Init(void)
{

  hi2c1.Instance = I2C1;
  hi2c1.Init.ClockSpeed = 400000;
  hi2c1.Init.DutyCycle = I2C_DUTYCYCLE_2;
  hi2c1.Init.OwnAddress1 = 0;
  hi2c1.Init.AddressingMode = I2C_ADDRESSINGMODE_7BIT;
  hi2c1.Init.DualAddressMode = I2C_DUALADDRESS_DISABLE;
  hi2c1.Init.OwnAddress2 = 0;
  hi2c1.Init.GeneralCallMode = I2C_GENERALCALL_DISABLE;
  hi2c1.Init.NoStretchMode = I2C_NOSTRETCH_DISABLE;
  if (HAL_I2C_Init(&hi2c1) != HAL_OK)
  {
    Error_Handler();
  }

}

static void MX_I2C2_Init(void)
{

  hi2c2.Instance = I2C2;
  hi2c2.Init.ClockSpeed = 50000;
  hi2c2.Init.DutyCycle = I2C_DUTYCYCLE_2;
  hi2c2.Init.OwnAddress1 = 0;
  hi2c2.Init.AddressingMode = I2C_ADDRESSINGMODE_7BIT;
  hi2c2.Init.DualAddressMode = I2C_DUALADDRESS_DISABLE;
  hi2c2.Init.OwnAddress2 = 0;
  hi2c2.Init.GeneralCallMode = I2C_GENERALCALL_DISABLE;
  hi2c2.Init.NoStretchMode = I2C_NOSTRETCH_DISABLE;
  if (HAL_I2C_Init(&hi2c2) != HAL_OK)
  {
    Error_Handler();
  }

}

static void MX_LTDC_Init(void)
{

  LTDC_LayerCfgTypeDef pLayerCfg = {0};

  hltdc.Instance = LTDC;
  hltdc.Init.HSPolarity = LTDC_HSPOLARITY_AL;
  hltdc.Init.VSPolarity = LTDC_VSPOLARITY_AL;
  hltdc.Init.DEPolarity = LTDC_DEPOLARITY_AL;
  hltdc.Init.PCPolarity = LTDC_PCPOLARITY_IPC;
  hltdc.Init.HorizontalSync = 1;
  hltdc.Init.VerticalSync = 1;
  hltdc.Init.AccumulatedHBP = 2;
  hltdc.Init.AccumulatedVBP = 2;
  hltdc.Init.AccumulatedActiveW = 202;
  hltdc.Init.AccumulatedActiveH = 482;
  hltdc.Init.TotalWidth = 203;
  hltdc.Init.TotalHeigh = 483;
  hltdc.Init.Backcolor.Blue = 0;
  hltdc.Init.Backcolor.Green = 0;
  hltdc.Init.Backcolor.Red = 0;
  if (HAL_LTDC_Init(&hltdc) != HAL_OK)
  {
    Error_Handler();
  }
  pLayerCfg.WindowX0 = 0;
  pLayerCfg.WindowX1 = 200;
  pLayerCfg.WindowY0 = 0;
  pLayerCfg.WindowY1 = 480;
  pLayerCfg.PixelFormat = LTDC_PIXEL_FORMAT_RGB565;
  pLayerCfg.Alpha = 255;
  pLayerCfg.Alpha0 = 0;
  pLayerCfg.BlendingFactor1 = LTDC_BLENDING_FACTOR1_CA;
  pLayerCfg.BlendingFactor2 = LTDC_BLENDING_FACTOR2_CA;
  pLayerCfg.FBStartAdress = 0xC0000000;
  pLayerCfg.ImageWidth = 200;
  pLayerCfg.ImageHeight = 480;
  pLayerCfg.Backcolor.Blue = 0;
  pLayerCfg.Backcolor.Green = 0;
  pLayerCfg.Backcolor.Red = 0;
  if (HAL_LTDC_ConfigLayer(&hltdc, &pLayerCfg, 0) != HAL_OK)
  {
    Error_Handler();
  }

}

static void MX_QUADSPI_Init(void)
{

  /* QUADSPI parameter configuration*/
  hqspi.Instance = QUADSPI;
  hqspi.Init.ClockPrescaler = 1;
  hqspi.Init.FifoThreshold = 1;
  hqspi.Init.SampleShifting = QSPI_SAMPLE_SHIFTING_HALFCYCLE;
  hqspi.Init.FlashSize = 27;
  hqspi.Init.ChipSelectHighTime = QSPI_CS_HIGH_TIME_5_CYCLE;
  hqspi.Init.ClockMode = QSPI_CLOCK_MODE_0;
  hqspi.Init.FlashID = QSPI_FLASH_ID_1;
  hqspi.Init.DualFlash = QSPI_DUALFLASH_DISABLE;
  if (HAL_QSPI_Init(&hqspi) != HAL_OK)
  {
    Error_Handler();
  }

}

static void MX_SDIO_SD_Init(void)
{

  hsd.Instance = SDIO;
  hsd.Init.ClockEdge = SDIO_CLOCK_EDGE_RISING;
  hsd.Init.ClockBypass = SDIO_CLOCK_BYPASS_DISABLE;
  hsd.Init.ClockPowerSave = SDIO_CLOCK_POWER_SAVE_DISABLE;
  hsd.Init.BusWide = SDIO_BUS_WIDE_1B;
  hsd.Init.HardwareFlowControl = SDIO_HARDWARE_FLOW_CONTROL_DISABLE;
  hsd.Init.ClockDiv = 0;

}

static void MX_SPI2_Init(void)
{

  /* SPI2 parameter configuration*/
  hspi2.Instance = SPI2;
  hspi2.Init.Mode = SPI_MODE_MASTER;
  hspi2.Init.Direction = SPI_DIRECTION_2LINES;
  hspi2.Init.DataSize = SPI_DATASIZE_8BIT;
  hspi2.Init.CLKPolarity = SPI_POLARITY_LOW;
  hspi2.Init.CLKPhase = SPI_PHASE_1EDGE;
  hspi2.Init.NSS = SPI_NSS_SOFT;
  hspi2.Init.BaudRatePrescaler = SPI_BAUDRATEPRESCALER_8;
  hspi2.Init.FirstBit = SPI_FIRSTBIT_MSB;
  hspi2.Init.TIMode = SPI_TIMODE_DISABLE;
  hspi2.Init.CRCCalculation = SPI_CRCCALCULATION_DISABLE;
  hspi2.Init.CRCPolynomial = 10;
  if (HAL_SPI_Init(&hspi2) != HAL_OK)
  {
    Error_Handler();
  }

}

static void MX_TIM2_Init(void)
{

  TIM_ClockConfigTypeDef sClockSourceConfig = {0};
  TIM_MasterConfigTypeDef sMasterConfig = {0};

  htim2.Instance = TIM2;
  htim2.Init.Prescaler = 9000 -1;
  htim2.Init.CounterMode = TIM_COUNTERMODE_UP;
  htim2.Init.Period = 10000;
  htim2.Init.ClockDivision = TIM_CLOCKDIVISION_DIV1;
  htim2.Init.AutoReloadPreload = TIM_AUTORELOAD_PRELOAD_DISABLE;
  if (HAL_TIM_Base_Init(&htim2) != HAL_OK)
  {
    Error_Handler();
  }
  sClockSourceConfig.ClockSource = TIM_CLOCKSOURCE_INTERNAL;
  if (HAL_TIM_ConfigClockSource(&htim2, &sClockSourceConfig) != HAL_OK)
  {
    Error_Handler();
  }
  sMasterConfig.MasterOutputTrigger = TIM_TRGO_RESET;
  sMasterConfig.MasterSlaveMode = TIM_MASTERSLAVEMODE_DISABLE;
  if (HAL_TIMEx_MasterConfigSynchronization(&htim2, &sMasterConfig) != HAL_OK)
  {
    Error_Handler();
  }

}

static void MX_TIM7_Init(void)
{

  TIM_MasterConfigTypeDef sMasterConfig = {0};

  htim7.Instance = TIM7;
  htim7.Init.Prescaler = 179;
  htim7.Init.CounterMode = TIM_COUNTERMODE_UP;
  htim7.Init.Period = 99;
  htim7.Init.AutoReloadPreload = TIM_AUTORELOAD_PRELOAD_DISABLE;
  if (HAL_TIM_Base_Init(&htim7) != HAL_OK)
  {
    Error_Handler();
  }
  sMasterConfig.MasterOutputTrigger = TIM_TRGO_RESET;
  sMasterConfig.MasterSlaveMode = TIM_MASTERSLAVEMODE_DISABLE;
  if (HAL_TIMEx_MasterConfigSynchronization(&htim7, &sMasterConfig) != HAL_OK)
  {
    Error_Handler();
  }

}

static void MX_USART6_UART_Init(void)
{

  huart6.Instance = USART6;
  huart6.Init.BaudRate = 9600;
  huart6.Init.WordLength = UART_WORDLENGTH_9B;
  huart6.Init.StopBits = UART_STOPBITS_1;
  huart6.Init.Parity = UART_PARITY_EVEN;
  huart6.Init.Mode = UART_MODE_TX_RX;
  huart6.Init.HwFlowCtl = UART_HWCONTROL_NONE;
  huart6.Init.OverSampling = UART_OVERSAMPLING_16;
  if (HAL_UART_Init(&huart6) != HAL_OK)
  {
    Error_Handler();
  }

}

static void MX_DMA_Init(void)
{

  /* DMA controller clock enable */
  __HAL_RCC_DMA2_CLK_ENABLE();

  /* DMA interrupt init */
  /* DMA2_Stream3_IRQn interrupt configuration */
  HAL_NVIC_SetPriority(DMA2_Stream3_IRQn, 5, 0);
  HAL_NVIC_EnableIRQ(DMA2_Stream3_IRQn);
  /* DMA2_Stream6_IRQn interrupt configuration */
  HAL_NVIC_SetPriority(DMA2_Stream6_IRQn, 5, 0);
  HAL_NVIC_EnableIRQ(DMA2_Stream6_IRQn);

}

/* FMC initialization function */
static void MX_FMC_Init(void)
{

  FMC_SDRAM_TimingTypeDef SdramTiming = {0};

  /** Perform the SDRAM1 memory initialization sequence
  */
  hsdram1.Instance = FMC_SDRAM_DEVICE;
  /* hsdram1.Init */
  hsdram1.Init.SDBank = FMC_SDRAM_BANK1;
  hsdram1.Init.ColumnBitsNumber = FMC_SDRAM_COLUMN_BITS_NUM_8;
  hsdram1.Init.RowBitsNumber = FMC_SDRAM_ROW_BITS_NUM_12;
  hsdram1.Init.MemoryDataWidth = FMC_SDRAM_MEM_BUS_WIDTH_32;
  hsdram1.Init.InternalBankNumber = FMC_SDRAM_INTERN_BANKS_NUM_4;
  hsdram1.Init.CASLatency = FMC_SDRAM_CAS_LATENCY_3;
  hsdram1.Init.WriteProtection = FMC_SDRAM_WRITE_PROTECTION_DISABLE;
  hsdram1.Init.SDClockPeriod = FMC_SDRAM_CLOCK_DISABLE;
  hsdram1.Init.ReadBurst = FMC_SDRAM_RBURST_ENABLE;
  hsdram1.Init.ReadPipeDelay = FMC_SDRAM_RPIPE_DELAY_2;
  /* SdramTiming */
  SdramTiming.LoadToActiveDelay = 2;
  SdramTiming.ExitSelfRefreshDelay = 7;
  SdramTiming.SelfRefreshTime = 4;
  SdramTiming.RowCycleDelay = 7;
  SdramTiming.WriteRecoveryTime = 3;
  SdramTiming.RPDelay = 2;
  SdramTiming.RCDDelay = 2;

  if (HAL_SDRAM_Init(&hsdram1, &SdramTiming) != HAL_OK)
  {
    Error_Handler( );
  }

}

static void MX_GPIO_Init(void)
{
  GPIO_InitTypeDef GPIO_InitStruct = {0};

  /* GPIO Ports Clock Enable */
  __HAL_RCC_GPIOG_CLK_ENABLE();
  __HAL_RCC_GPIOE_CLK_ENABLE();
  __HAL_RCC_GPIOB_CLK_ENABLE();
  __HAL_RCC_GPIOC_CLK_ENABLE();
  __HAL_RCC_GPIOD_CLK_ENABLE();
  __HAL_RCC_GPIOA_CLK_ENABLE();
  __HAL_RCC_GPIOI_CLK_ENABLE();
  __HAL_RCC_GPIOF_CLK_ENABLE();
  __HAL_RCC_GPIOK_CLK_ENABLE();
  __HAL_RCC_GPIOH_CLK_ENABLE();
  __HAL_RCC_GPIOJ_CLK_ENABLE();

  /*Configure GPIO pin Output Level */
  HAL_GPIO_WritePin(GPIOD, GPIO_PIN_5|GPIO_PIN_4, GPIO_PIN_SET);

  /*Configure GPIO pin Output Level */
  HAL_GPIO_WritePin(GPIOK, GPIO_PIN_3, GPIO_PIN_RESET);

  /*Configure GPIO pin Output Level */
  HAL_GPIO_WritePin(Green_LED_GPIO_Port, Green_LED_Pin, GPIO_PIN_SET);

  /*Configure GPIO pin Output Level */
  HAL_GPIO_WritePin(GPIOA, GPIO_PIN_4, GPIO_PIN_RESET);

  /*Configure GPIO pin Output Level */
  HAL_GPIO_WritePin(GPIOC, GPIO_PIN_4, GPIO_PIN_RESET);

  /*Configure GPIO pin Output Level */
  HAL_GPIO_WritePin(GPIOH, GPIO_PIN_7|SPI_CS_Pin, GPIO_PIN_RESET);

  /*Configure GPIO pins : PD5 PD4 */
  GPIO_InitStruct.Pin = GPIO_PIN_5|GPIO_PIN_4;
  GPIO_InitStruct.Mode = GPIO_MODE_OUTPUT_OD;
  GPIO_InitStruct.Pull = GPIO_NOPULL;
  GPIO_InitStruct.Speed = GPIO_SPEED_FREQ_LOW;
  HAL_GPIO_Init(GPIOD, &GPIO_InitStruct);

  /*Configure GPIO pin : PK3 */
  GPIO_InitStruct.Pin = GPIO_PIN_3;
  GPIO_InitStruct.Mode = GPIO_MODE_OUTPUT_PP;
  GPIO_InitStruct.Pull = GPIO_NOPULL;
  GPIO_InitStruct.Speed = GPIO_SPEED_FREQ_LOW;
  HAL_GPIO_Init(GPIOK, &GPIO_InitStruct);

  /*Configure GPIO pin : Green_LED_Pin */
  GPIO_InitStruct.Pin = Green_LED_Pin;
  GPIO_InitStruct.Mode = GPIO_MODE_OUTPUT_OD;
  GPIO_InitStruct.Pull = GPIO_NOPULL;
  GPIO_InitStruct.Speed = GPIO_SPEED_FREQ_LOW;
  HAL_GPIO_Init(Green_LED_GPIO_Port, &GPIO_InitStruct);

  /*Configure GPIO pin : PG2 */
  GPIO_InitStruct.Pin = GPIO_PIN_2;
  GPIO_InitStruct.Mode = GPIO_MODE_INPUT;
  GPIO_InitStruct.Pull = GPIO_NOPULL;
  HAL_GPIO_Init(GPIOG, &GPIO_InitStruct);

  /*Configure GPIO pins : PA1 PA2 */
  GPIO_InitStruct.Pin = GPIO_PIN_1|GPIO_PIN_2;
  GPIO_InitStruct.Mode = GPIO_MODE_INPUT;
  GPIO_InitStruct.Pull = GPIO_NOPULL;
  HAL_GPIO_Init(GPIOA, &GPIO_InitStruct);

  /*Configure GPIO pin : PA4 */
  GPIO_InitStruct.Pin = GPIO_PIN_4;
  GPIO_InitStruct.Mode = GPIO_MODE_OUTPUT_PP;
  GPIO_InitStruct.Pull = GPIO_NOPULL;
  GPIO_InitStruct.Speed = GPIO_SPEED_FREQ_LOW;
  HAL_GPIO_Init(GPIOA, &GPIO_InitStruct);

  /*Configure GPIO pin : PC4 */
  GPIO_InitStruct.Pin = GPIO_PIN_4;
  GPIO_InitStruct.Mode = GPIO_MODE_OUTPUT_PP;
  GPIO_InitStruct.Pull = GPIO_NOPULL;
  GPIO_InitStruct.Speed = GPIO_SPEED_FREQ_LOW;
  HAL_GPIO_Init(GPIOC, &GPIO_InitStruct);

  /*Configure GPIO pin : PH7 */
  GPIO_InitStruct.Pin = GPIO_PIN_7;
  GPIO_InitStruct.Mode = GPIO_MODE_OUTPUT_OD;
  GPIO_InitStruct.Pull = GPIO_NOPULL;
  GPIO_InitStruct.Speed = GPIO_SPEED_FREQ_VERY_HIGH;
  HAL_GPIO_Init(GPIOH, &GPIO_InitStruct);

  /*Configure GPIO pins : PA6 PA7 */
  GPIO_InitStruct.Pin = GPIO_PIN_6|GPIO_PIN_7;
  GPIO_InitStruct.Mode = GPIO_MODE_AF_PP;
  GPIO_InitStruct.Pull = GPIO_NOPULL;
  GPIO_InitStruct.Speed = GPIO_SPEED_FREQ_VERY_HIGH;
  GPIO_InitStruct.Alternate = GPIO_AF5_SPI1;
  HAL_GPIO_Init(GPIOA, &GPIO_InitStruct);

  /*Configure GPIO pin : PA5 */
  GPIO_InitStruct.Pin = GPIO_PIN_5;
  GPIO_InitStruct.Mode = GPIO_MODE_ANALOG;
  GPIO_InitStruct.Pull = GPIO_NOPULL;
  HAL_GPIO_Init(GPIOA, &GPIO_InitStruct);

  /*Configure GPIO pin : SPI_CS_Pin */
  GPIO_InitStruct.Pin = SPI_CS_Pin;
  GPIO_InitStruct.Mode = GPIO_MODE_OUTPUT_PP;
  GPIO_InitStruct.Pull = GPIO_NOPULL;
  GPIO_InitStruct.Speed = GPIO_SPEED_FREQ_LOW;
  HAL_GPIO_Init(SPI_CS_GPIO_Port, &GPIO_InitStruct);

}

void StartDefaultTask(void *argument)
{
  for(;;)
  {
    osDelay(1);
  }
}

void StartStateTask(void *argument)
{
  for(;;)
  {
    osDelay(1);
  }
}

void StartOutTask(void *argument)
{
  for(;;)
  {
    osDelay(1);
  }
}

void StartModeTask(void *argument)
{
  for(;;)
  {
    osDelay(1);
  }
}

void StartTimeTask(void *argument)
{
  for(;;)
  {
    osDelay(1);
  }
}

void StartCAN2TxTask(void *argument)
{
  for(;;)
  {
    osDelay(1);
  }
}

void StartSDTask(void *argument)
{
  for(;;)
  {
    osDelay(1);
  }
}

void StartCAN1RxTxTask(void *argument)
{
  for(;;)
  {
    osDelay(1);
  }
}

void StartAlarmTask(void *argument)
{
  for(;;)
  {
    osDelay(1);
  }
}

void StartRequestTask(void *argument)
{
  for(;;)
  {
    osDelay(1);
  }
}

void StartCAN1_ReceiveTask(void *argument)
{
  for(;;)
  {
    osDelay(1);
  }
}

void StartCAN1_TransmitTask(void *argument)
{
  for(;;)
  {
    osDelay(1);
  }
}

void StartAcquisitionTask(void *argument)
{
  for(;;)
  {
    osDelay(1);
  }
}

void HAL_TIM_PeriodElapsedCallback(TIM_HandleTypeDef *htim)
{
  if (htim->Instance == TIM6) {
    HAL_IncTick();
  }
}

void Error_Handler(void)
{
  __disable_irq();
  while (1)
  {
  }
}

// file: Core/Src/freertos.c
/* USER CODE BEGIN Header */
/**
  ******************************************************************************
  * File Name          : freertos.c
  * Description        : Code for freertos applications
  ******************************************************************************
  * @attention
  *
  * Copyright (c) 2023 STMicroelectronics.
  * All rights reserved.
  *
  * This software is licensed under terms that can be found in the LICENSE file
  * in the root directory of this software component.
  * If no LICENSE file comes with this software, it is provided AS-IS.
  *
  ******************************************************************************
  */
/* USER CODE END Header */

#include <main.h>
#include "FreeRTOS.h"
#include "task.h"

/* Hook prototypes */
void configureTimerForRunTimeStats(void);
unsigned long getRunTimeCounterValue(void);
void vApplicationIdleHook(void);

/* USER CODE BEGIN 1 */
/* Functions needed when configGENERATE_RUN_TIME_STATS is on */
__weak void configureTimerForRunTimeStats(void)
{

}

__weak unsigned long getRunTimeCounterValue(void)
{
return 0;
}
/* USER CODE END 1 */

/* USER CODE BEGIN 2 */
void vApplicationIdleHook( void )
{
   /* vApplicationIdleHook() will only be called if configUSE_IDLE_HOOK is set
   to 1 in FreeRTOSConfig.h. It will be called on each iteration of the idle
   task. It is essential that code added to this hook function never attempts
   to block in any way (for example, call xQueueReceive() with a block time
   specified, or call vTaskDelay()). If the application makes use of the
   vTaskDelete() API function (as this demo application does) then it is also
   important that vApplicationIdleHook() is permitted to return to its calling
   function, because it is the responsibility of the idle task to clean up
   memory allocated by the kernel to any task that has since been deleted. */
}
/* USER CODE END 2 */
